# SLIMBUS2_L3Interconnect register map
Vendor: Texas Instruments
Peripheral module from a debugger description file (folder omap4460).
Registers are 32-bit, access per field, reset 0x0 unless marked. A register's access mark holds for its fields unless they carry their own. Offsets are as the file gives them; lines under a group give offsets from that group; [hi:lo] are bit positions; {n}, {i} and the like mark numbered series; 'fields as' and 'values as' point back to an identical list; <NAME> marks a mode.

## SLIMBUS2_L3Interconnect (part 1 of 2)
0x00 SLIMBUS_CMP_REVISION ro reset not defined — IP Revision Identifier Used by software to track features, bugs, and compatibility
  [31:0] REVISION — Revision Number
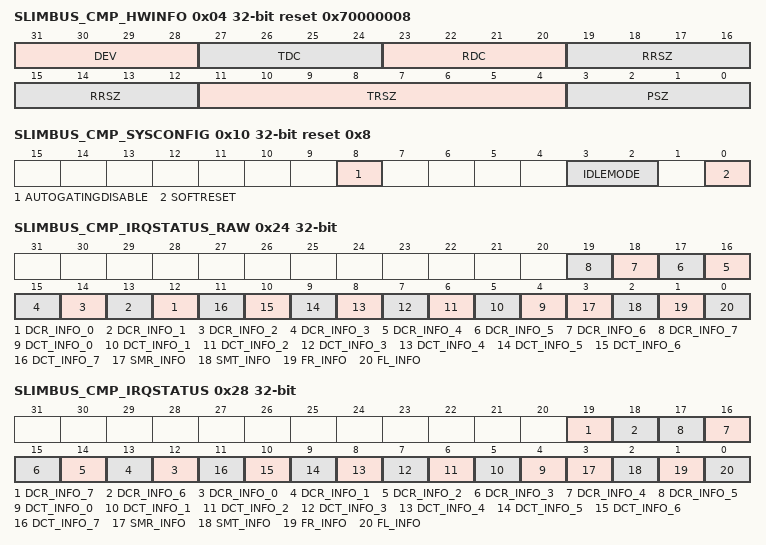
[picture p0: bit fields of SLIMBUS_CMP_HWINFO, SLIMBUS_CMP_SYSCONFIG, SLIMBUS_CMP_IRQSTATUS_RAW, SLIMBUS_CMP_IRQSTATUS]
0x04 SLIMBUS_CMP_HWINFO ro reset 0x70000008 (reset mask 0xF000000F) — Those read-only, hardcoded fields display the values of the eponymous hardware configuration depending on module instantiation - SLIMBUS1 or SLIMBUS2.
  [31:28] DEV — Device count: number of devices supported by the component, most notably through the automatically reception of the messages addressed to them. Sets the number of instances of the 'DEV_XYZ' registers.
  [27:24] TDC — Transmit Data agent Count: Number of transmit hardware data agents (FIFO and associated logic) Sets the number of instances of the 'DCT_XYZ' registers.
  [23:20] RDC — Receive Data agent Count: Number of receive hardware data agents (FIFO and associated logic) Sets the number of instances of the 'DCR_XYZ' registers.
  [19:12] RRSZ — Size of receive FIFO RAM, in 32-bit words. RX message FIFO and all RX data FIFOs map to that shared RAM.
  [11:4] TRSZ — Size of transmit FIFO RAM, in 32-bit words. TX message FIFO and all TX data FIFOs map to that shared RAM.
  [3:0] PSZ — Size of (both TX and RX) FIFO segment word pointers, in bits. Determines the maximum number of (variable-sized) segment words a data agent FIFO can contain. Sets the width of FIFO control and status fields: size, threshold, level.
0x10 SLIMBUS_CMP_SYSCONFIG reset 0x8 — This register allows controlling various parameters of the interconnect interface
  [8] AUTOGATINGDISABLE rw — Control of the internal clock autogating for safety / debug only. No impact on module functionality, only on dynamic power.
    0=Internal clocks are gated off when unused, power is optimized; 1=Internal clocks are free-running, maximum dynamic power
  [3:2] IDLEMODE rw — Configuration of the local target state management mode. By definition, target can handle read/write transaction as long as it is out of IDLE state.
    0=Force-idle mode: local target's idle state follows (acknowledges) the system's idle requests unconditionally, that is, regardless of the IP module's internal requirements. Backup mode, for debug only.; 1=No-idle mode: local target never enters idle state. Backup mode, for debug only.; 3=Smart-idle wakeup-capable mode: local target's idle state eventually follows (acknowledges) the system's idle requests, depending on the IP module's internal requirements. IP module may generate (IRQ- or DMA-request-related) wakeup events when in idle state. Mode is only relevant if the appropriate IP module 'swakeup' output(s) is (are) implemented.; 2=Smart-idle mode: local target's idle state eventually follows (acknowledges) the system's idle requests, depending on the IP module's internal requirements. IP module shall not generate (IRQ- or DMA-request-related) wakeup events.
  [0] SOFTRESET rw — Software reset. (Optional)
    0=SOFTRESET_0_w (No action); 1=SOFTRESET_1_w (Initiate software reset); 1=SOFTRESET_1_r (Reset (software or other) ongoing); 0=SOFTRESET_0_r (Reset done, no pending action)
0x24 SLIMBUS_CMP_IRQSTATUS_RAW access not given — Component (that is, main) interrupt request status. Check the corresponding secondary status register. Raw status is set even if event is not enabled. Write 1 to set the (raw) status, mostly for debug.
  [n+12] DCR_INFO_{n} (n=0..7) — IRQ status for RX Data agent {n} If implemented: (access RW W1toSet)
    0=DCR_INFO_{n}_0_w (No action); 1=DCR_INFO_{n}_1_w (Trigger IRQ event by software); 1=DCR_INFO_{n}_1_r (IRQ event pending); 0=DCR_INFO_{n}_0_r (No event pending)
  [n+4] DCT_INFO_{n} (n=0..7) — IRQ status for TX Data agent {n} (access RW W1toSet)
    0=DCT_INFO_{n}_0_w (No action); 1=DCT_INFO_{n}_1_w (Trigger IRQ event by software); 1=DCT_INFO_{n}_1_r (IRQ event pending); 0=DCT_INFO_{n}_0_r (No event pending)
  [3] SMR_INFO — IRQ status for message receive (access RW W1toSet)
    0=SMR_INFO_0_w (No action); 1=SMR_INFO_1_w (Trigger IRQ event by software); 1=SMR_INFO_1_r (IRQ event pending); 0=SMR_INFO_0_r (No event pending)
  [2] SMT_INFO — IRQ status for message transmit (access RW W1toSet)
    0=SMT_INFO_0_w (No action); 1=SMT_INFO_1_w (Trigger IRQ event by software); 1=SMT_INFO_1_r (IRQ event pending); 0=SMT_INFO_0_r (No event pending)
  [1] FR_INFO — IRQ status for Framer device, when active (access RW W1toSet)
    0=FR_INFO_0_w (No action); 1=FR_INFO_1_w (Trigger IRQ event by software); 1=FR_INFO_1_r (IRQ event pending); 0=FR_INFO_0_r (No event pending)
  [0] FL_INFO — IRQ status for Frame Layer (access RW W1toSet)
    0=FL_INFO_0_w (No action); 1=FL_INFO_1_w (Trigger IRQ event by software); 1=FL_INFO_1_r (IRQ event pending); 0=FL_INFO_0_r (No event pending)
0x28 SLIMBUS_CMP_IRQSTATUS access not given — Component (that is, main) interrupt request status. Check the corresponding secondary status register. Enabled status isn't set unless event is enabled. Write 1 to clear the status after interrupt has been serviced (raw status gets cleared, that is, even if not enabled).
  [19] DCR_INFO_7 — IRQ status for RX Data agent 7. If implemented: (access RW W1toClr)
    0=DCR_INFO_7_0_w (No action); 1=DCR_INFO_7_1_w (Clear pending event, if any); 1=DCR_INFO_7_1_r (IRQ event pending); 0=DCR_INFO_7_0_r (No event pending)
  [18] DCR_INFO_6 — IRQ status for RX Data agent 6. If implemented: (access RW W1toClr)
    0=DCR_INFO_6_0_w (No action); 1=DCR_INFO_6_1_w (Clear pending event, if any); 1=DCR_INFO_6_1_r (IRQ event pending); 0=DCR_INFO_6_0_r (No event pending)
  [n+12] DCR_INFO_{n} (n=0..5) — IRQ status for RX Data agent {n} . If implemented: (access RW W1toClr)
    0=DCR_INFO_{n}_0_w (No action); 1=DCR_INFO_{n}_1_w (Clear pending event, if any); 1=DCR_INFO_{n}_1_r (IRQ event pending); 0=DCR_INFO_{n}_0_r (No event pending)
  [n+4] DCT_INFO_{n} (n=0..7) — IRQ status for TX Data agent {n} (access RW W1toClr)
    0=DCT_INFO_{n}_0_w (No action); 1=DCT_INFO_{n}_1_w (Clear pending event, if any); 1=DCT_INFO_{n}_1_r (IRQ event pending); 0=DCT_INFO_{n}_0_r (No event pending)
  [3] SMR_INFO — IRQ status for message receive (access RW W1toClr)
    0=SMR_INFO_0_w (No action); 1=SMR_INFO_1_w (Clear pending event, if any); 1=SMR_INFO_1_r (IRQ event pending); 0=SMR_INFO_0_r (No event pending)
  [2] SMT_INFO — IRQ status for message transmit (access RW W1toClr)
    0=SMT_INFO_0_w (No action); 1=SMT_INFO_1_w (Clear pending event, if any); 1=SMT_INFO_1_r (IRQ event pending); 0=SMT_INFO_0_r (No event pending)
  [1] FR_INFO — IRQ status for Framer device, when active (access RW W1toClr)
    0=FR_INFO_0_w (No action); 1=FR_INFO_1_w (Clear pending event, if any); 1=FR_INFO_1_r (IRQ event pending); 0=FR_INFO_0_r (No event pending)
  [0] FL_INFO — IRQ status for Frame Layer (access RW W1toClr)
    0=FL_INFO_0_w (No action); 1=FL_INFO_1_w (Clear pending event, if any); 1=FL_INFO_1_r (IRQ event pending); 0=FL_INFO_0_r (No event pending)
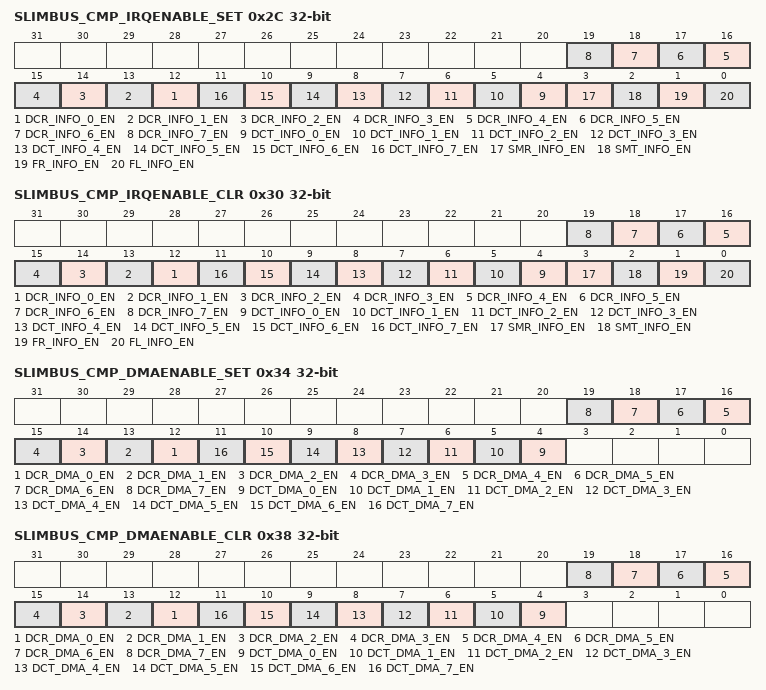
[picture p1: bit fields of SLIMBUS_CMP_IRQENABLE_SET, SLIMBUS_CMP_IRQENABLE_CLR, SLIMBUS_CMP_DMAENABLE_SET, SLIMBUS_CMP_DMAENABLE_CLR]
0x2C SLIMBUS_CMP_IRQENABLE_SET access not given — Component (that is, main) interrupt request enable Write 1 to set (enable interrupt). Readout equal to corresponding _CLR register.
  [n+12] DCR_INFO_{n}_EN (n=0..7) — IRQ enable for RX Data agent {n}. If implemented: (access RW W1toSet)
    0=DCR_INFO_{n}_EN_0_w (No action); 1=DCR_INFO_{n}_EN_1_w (Set IRQ enable (that is, enable event)); 1=DCR_INFO_{n}_EN_1_r (IRQ event is enabled); 0=DCR_INFO_{n}_EN_0_r (IRQ event is disabled)
  [n+4] DCT_INFO_{n}_EN (n=0..7) — IRQ enable for TX Data agent {n} (access RW W1toSet)
    0=DCT_INFO_{n}_EN_0_w (No action); 1=DCT_INFO_{n}_EN_1_w (Set IRQ enable (that is, enable event)); 1=DCT_INFO_{n}_EN_1_r (IRQ event is enabled); 0=DCT_INFO_{n}_EN_0_r (IRQ event is disabled)
  [3] SMR_INFO_EN — IRQ enable for message receive (access RW W1toSet)
    0=SMR_INFO_EN_0_w (No action); 1=SMR_INFO_EN_1_w (Set IRQ enable (that is, enable event)); 1=SMR_INFO_EN_1_r (IRQ event is enabled); 0=SMR_INFO_EN_0_r (IRQ event is disabled)
  [2] SMT_INFO_EN — IRQ enable for message transmit (access RW W1toSet)
    0=SMT_INFO_EN_0_w (No action); 1=SMT_INFO_EN_1_w (Set IRQ enable (that is, enable event)); 1=SMT_INFO_EN_1_r (IRQ event is enabled); 0=SMT_INFO_EN_0_r (IRQ event is disabled)
  [1] FR_INFO_EN — IRQ enable for Framer device, when active (access RW W1toSet)
    0=FR_INFO_EN_0_w (No action); 1=FR_INFO_EN_1_w (Set IRQ enable (that is, enable event)); 1=FR_INFO_EN_1_r (IRQ event is enabled); 0=FR_INFO_EN_0_r (IRQ event is disabled)
  [0] FL_INFO_EN — IRQ enable for Frame Layer (access RW W1toSet)
    0=FL_INFO_EN_0_w (No action); 1=FL_INFO_EN_1_w (Set IRQ enable (that is, enable event)); 1=FL_INFO_EN_1_r (IRQ event is enabled); 0=FL_INFO_EN_0_r (IRQ event is disabled)
0x30 SLIMBUS_CMP_IRQENABLE_CLR access not given — Component (that is, main) interrupt request enable Write 1 to clear (disable interrupt). Readout equal to corresponding _SET register.
  [n+12] DCR_INFO_{n}_EN (n=0..7) — IRQ enable for RX data agent {n}. If implemented: (access RW W1toClr)
    0=DCR_INFO_{n}_EN_0_w (No action); 1=DCR_INFO_{n}_EN_1_w (Clear IRQ enable (that is, disable event)); 1=DCR_INFO_{n}_EN_1_r (IRQ event is enabled); 0=DCR_INFO_{n}_EN_0_r (IRQ event is disabled)
  [n+4] DCT_INFO_{n}_EN (n=0..7) — IRQ enable for TX Data agent {n} (access RW W1toClr)
    0=DCT_INFO_{n}_EN_0_w (No action); 1=DCT_INFO_{n}_EN_1_w (Clear IRQ enable (that is, disable event)); 1=DCT_INFO_{n}_EN_1_r (IRQ event is enabled); 0=DCT_INFO_{n}_EN_0_r (IRQ event is disabled)
  [3] SMR_INFO_EN — IRQ enable for message receive (access RW W1toClr)
    0=SMR_INFO_EN_0_w (No action); 1=SMR_INFO_EN_1_w (Clear IRQ enable (that is, disable event)); 1=SMR_INFO_EN_1_r (IRQ event is enabled); 0=SMR_INFO_EN_0_r (IRQ event is disabled)
  [2] SMT_INFO_EN — IRQ enable for message transmit (access RW W1toClr)
    0=SMT_INFO_EN_0_w (No action); 1=SMT_INFO_EN_1_w (Clear IRQ enable (that is, disable event)); 1=SMT_INFO_EN_1_r (IRQ event is enabled); 0=SMT_INFO_EN_0_r (IRQ event is disabled)
  [1] FR_INFO_EN — IRQ enable for Framer device, when active (access RW W1toClr)
    0=FR_INFO_EN_0_w (No action); 1=FR_INFO_EN_1_w (Clear IRQ enable (that is, disable event)); 1=FR_INFO_EN_1_r (IRQ event is enabled); 0=FR_INFO_EN_0_r (IRQ event is disabled)
  [0] FL_INFO_EN — IRQ enable for Frame Layer (access RW W1toClr)
    0=FL_INFO_EN_0_w (No action); 1=FL_INFO_EN_1_w (Clear IRQ enable (that is, disable event)); 1=FL_INFO_EN_1_r (IRQ event is enabled); 0=FL_INFO_EN_0_r (IRQ event is disabled)
0x34 SLIMBUS_CMP_DMAENABLE_SET access not given — Components DMA enable (1 bit per DMA-capable channel) Write 1 to set (enable DMA). Readout equal to corresponding _CLR register.
  [n+12] DCR_DMA_{n}_EN (n=0..7) — DMA enable for RX Data agent {n} . If implemented: (access RW W1toSet.)
    0=DCR_DMA_{n}_EN_0_w (No action); 1=DCR_DMA_{n}_EN_1_w (Set DMA enable (that is, enable channel)); 1=DCR_DMA_{n}_EN_1_r (DMA channel is enabled); 0=DCR_DMA_{n}_EN_0_r (DMA chanel is disabled)
  [n+4] DCT_DMA_{n}_EN (n=0..7) — DMA enable for TX Data agent {n} (access RW W1toSet)
    0=DCT_DMA_{n}_EN_0_w (No action); 1=DCT_DMA_{n}_EN_1_w (Set DMA enable (that is, enable channel)); 1=DCT_DMA_{n}_EN_1_r (DMA channel is enabled); 0=DCT_DMA_{n}_EN_0_r (DMA chanel is disabled)
0x38 SLIMBUS_CMP_DMAENABLE_CLR access not given — Components DMA enable (1 bit per DMA-capable channel) Write 1 to clear (disable DMA). Readout equal to corresponding _SET register.
  [n+12] DCR_DMA_{n}_EN (n=0..7) — DMA enable for RX Data agent {n} . If implemented: (access RW W1toClr)
    0=DCR_DMA_{n}_EN_0_w (No action); 1=DCR_DMA_{n}_EN_1_w (Clear DMA enable (that is, disable channel)); 1=DCR_DMA_{n}_EN_1_r (DMA channel is enabled); 0=DCR_DMA_{n}_EN_0_r (DMA chanel is disabled)
  [n+4] DCT_DMA_{n}_EN (n=0..7) — DMA enable for TX Data agent {n} (access RW W1toClr)
    0=DCT_DMA_{n}_EN_0_w (No action); 1=DCT_DMA_{n}_EN_1_w (Clear DMA enable (that is, disable channel)); 1=DCT_DMA_{n}_EN_1_r (DMA channel is enabled); 0=DCT_DMA_{n}_EN_0_r (DMA chanel is disabled)
0x40 SLIMBUS_CMP_IV — Component IV field, used as lower 8 bits of the devices' Enumeration Address (EA[47:0]). Identical for all devices of the component.
  [7:0] IV rw — Device component's Instance Value (IV[7:0])
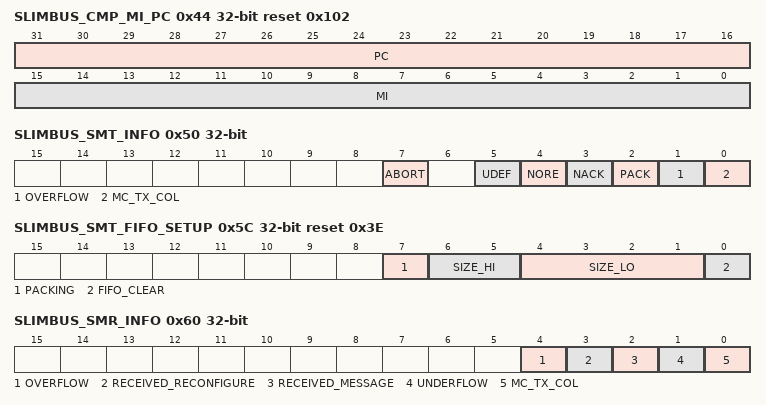
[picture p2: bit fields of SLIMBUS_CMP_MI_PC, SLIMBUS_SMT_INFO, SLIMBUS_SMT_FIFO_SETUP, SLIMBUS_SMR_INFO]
0x44 SLIMBUS_CMP_MI_PC rw reset 0x102 — Component MI and PC fields, used as upper 32 bits of the devices' Enumeration Address (EA[47:0]). Identical for all devices of the component.
  [31:16] PC — Device component's Product Code (PC[15:0])
  [15:0] MI — Device component's Manufacturer Index (MI[15:0])
0x50 SLIMBUS_SMT_INFO access not given — IRQ status for Shared Message Transmit channel. Write 1 to a bit to clear it.
  [7] ABORT — TX message was aborted before completion because of message sync loss. (access RW W1toClr)
    0=ABORT_0_w (No action); 1=ABORT_1_w (Clear pending event, if any); 1=ABORT_1_r (IRQ event pending); 0=ABORT_0_r (No event pending)
  [5] UDEF — TX message was UDEF'ed: undefined response, protocol error. (access RW W1toClr)
    0=UDEF_0_w (No action); 1=UDEF_1_w (Clear pending event, if any); 1=UDEF_1_r (IRQ event pending); 0=UDEF_0_r (No event pending)
  [4] NORE — TX message was NORE'ed: no or all-zero message response (access RW W1toClr)
    0=NORE_0_w (No action); 1=NORE_1_w (Clear pending event, if any); 1=NORE_1_r (IRQ event pending); 0=NORE_0_r (No event pending)
  [3] NACK — TX message was NACK'ed: at least one of the recipient devices requested message retransmission. (access RW W1toClr)
    0=NACK_0_w (No action); 1=NACK_1_w (Clear pending event, if any); 1=NACK_1_r (IRQ event pending); 0=NACK_0_r (No event pending)
  [2] PACK — TX message was PACK'ed: all recipient devices accepted the message. (access RW W1toClr)
    0=PACK_0_w (No action); 1=PACK_1_w (Clear pending event, if any); 1=PACK_1_r (IRQ event pending); 0=PACK_0_r (No event pending)
  [1] OVERFLOW — Overflow in TX message FIFO: Software tried to write more bytes than available in the FIFO. (access RW W1toClr)
    0=OVERFLOW_0_w (No action); 1=OVERFLOW_1_w (Clear pending event, if any); 1=OVERFLOW_1_r (IRQ event pending); 0=OVERFLOW_0_r (No event pending)
  [0] MC_TX_COL — Transmit collision in Message Channel (MC) during message transmission. Interface device class-specific information element (IE) (access RW W1toClr)
    0=MC_TX_COL_0_w (No action); 1=MC_TX_COL_1_w (Clear pending event, if any); 1=MC_TX_COL_1_r (IRQ event pending); 0=MC_TX_COL_0_r (No event pending)
0x54 SLIMBUS_SMT_MESSAGE rw — Shared Message Transmit FIFO input
  [31:0] TX_MESSAGE — TX message byte(s), depending on packing mode. Reads return 0. Enter the whole message except last byte (Message Integrity MI and Response MR), and with a don't care placeholder for Primary Integrity (PI).
0x58 SLIMBUS_SMT_CONTROL — Control of Shared Message channel Transmission.
  [0] MESSAGE_ENABLE rw — Enable the transmission of the message(s) previously written into the TX Message FIFO, with unlimited arbitration auto-retries. Self-cleared after either a message not get PACK'ed or the FIFO is empty.
    0=MESSAGE_ENABLE_0_w (No effect); 1=MESSAGE_ENABLE_1_w (Request transmission of stored messages); 1=MESSAGE_ENABLE_1_r (Message transmission is ongoing); 0=MESSAGE_ENABLE_0_r (Message transmission is stopped / complete)
0x5C SLIMBUS_SMT_FIFO_SETUP reset 0x3E — Shared Message Transmit channel configuration. To be kept static during operation. Note that message segment word size is 2 slots = 1 byte (= message size granularity) and that message FIFO base address is always 0x0.
  [7] PACKING rw — Packing enable control for TX message FIFO
    0=Packing disabled: one byte per access only (LSByte), byte enable is don't care; 1=Packing enabled: one or several bytes per access, depending on byte enable
  [6:5] SIZE_HI rw — (Upper bits of the) capacity of shared TX message FIFO, in bytes, minus one. To be set for largest supported (transmitted) message(s).
    0=16 bytes (minimum size); 1=32 bytes (recommended); 3=64 bytes (max size); 2=48 bytes (large messages)
  [4:1] SIZE_LO ro — (Lower bits of the) capacity of shared TX message FIFO, in bytes, minus one. Read-only, for reference only.
  [0] FIFO_CLEAR rw — Returns FIFO to initial empty state.
    0=FIFO_CLEAR_0_w (No effect); 1=FIFO_CLEAR_1_w (Clear FIFO); 1=FIFO_CLEAR_1_r (Ongoing Clear. Completion requires the SLIMbus clock.); 0=FIFO_CLEAR_0_r (No event, last clear completed)
0x60 SLIMBUS_SMR_INFO access not given — IRQ status for Shared Message Receive channel. Write 1 to a bit to clear it.
  [4] OVERFLOW — Overflow in RX message FIFO: received message is larger than the FIFO. (access RW W1toClr)
    0=OVERFLOW_0_w (no action); 1=OVERFLOW_1_w (clear event); 1=OVERFLOW_1_r (event pending); 0=OVERFLOW_0_r (no event pending)
  [3] RECEIVED_RECONFIGURE — RECONFIGURE_NOW message received, available in RX message FIFO (access RW W1toClr)
    0=RECEIVED_RECONFIGURE_0_w (no action); 1=RECEIVED_RECONFIGURE_1_w (clear event); 1=RECEIVED_RECONFIGURE_1_r (event pending); 0=RECEIVED_RECONFIGURE_0_r (no event pending)
  [2] RECEIVED_MESSAGE — Message available in the RX message FIFO. Clear bit to clear the FIFO and allow the reception of further messages (incoming messages will be NACK'ed until then). (access RW W1toClr)
    0=RECEIVED_MESSAGE_0_w (no action); 1=RECEIVED_MESSAGE_1_w (clear event, clear FIFO, allow further messages.); 1=RECEIVED_MESSAGE_1_r (event pending); 0=RECEIVED_MESSAGE_0_r (no event pending)
  [1] UNDERFLOW — Underflow in RX message FIFO: Software tried to read out more bytes than available. (access RW W1toClr)
    0=UNDERFLOW_0_w (no action); 1=UNDERFLOW_1_w (clear event); 1=UNDERFLOW_1_r (event pending); 0=UNDERFLOW_0_r (no event pending)
  [0] MC_TX_COL — Transmit collision in Message Channel (MC) during RX message during message reception. Interface device class-specific information element (IE) (access RW W1toClr)
    0=MC_TX_COL_0_w (no action); 1=MC_TX_COL_1_w (clear event); 1=MC_TX_COL_1_r (event pending); 0=MC_TX_COL_0_r (no event pending)
0x64 SLIMBUS_SMR_MESSAGE ro — Shared Message Receive channel FIFO output.
  [31:0] RX_MESSAGE — RX message byte(s), depending on packing mode. Writes have no effect. Readout value from an empty FIFO is undefined, that is, there is no defined 'reset value'. Message is guaranteed to have destination address matching a local device address (LA or EA), correct Primary and Message Integrity (PI and MI) and PACK Message Response (MR). Whole message available for readout, including the last byte (Message Integrity MI and Response MR)
0x68 SLIMBUS_SMR_CONTROL — Control of Shared Message channel Reception.
  [0] MESSAGE_DISABLE rw — Disables the reception of incoming messages (that is, broadcast or locally addressed) into the RX Message FIFO. Same effect for the same value than SMR_INFO[2] RECEIVED_MESSAGE, but this bit can be set to 1.
    0=Enabled: incoming messages will be PACK'ed; 1=Disabled: incoming messages will be NACK'ed
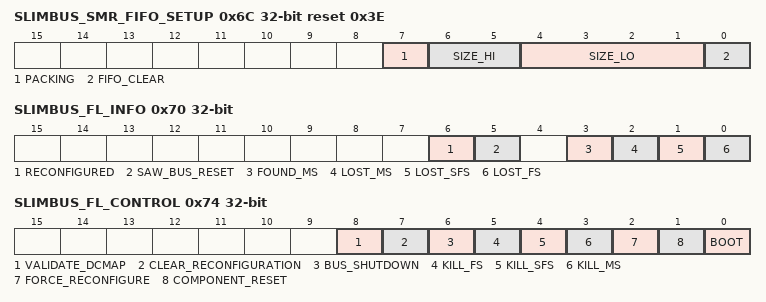
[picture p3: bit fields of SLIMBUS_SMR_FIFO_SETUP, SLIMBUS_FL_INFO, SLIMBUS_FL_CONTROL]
0x6C SLIMBUS_SMR_FIFO_SETUP reset 0x3E — Shared Message Receive channel setup. To be kept static during operation. Note that message segment word size is 2 slots = 1 byte (= message size granularity) and that message FIFO base address is always 0x0.
  [7] PACKING rw — Packing enable control for RX message FIFO
    values as SLIMBUS_SMT_FIFO_SETUP.PACKING
  [6:5] SIZE_HI rw — (Upper bits of the) capacity of shared RX message FIFO, in bytes, minus one. To be set for largest supported (received) message.
    values as SLIMBUS_SMT_FIFO_SETUP.SIZE_HI
  [4:1] SIZE_LO ro — (Lower bits of the) capacity of shared RX message FIFO, in bytes, minus one. Read-only, for reference only.
  [0] FIFO_CLEAR rw — Returns message FIFO to initial empty state.
    values as SLIMBUS_SMT_FIFO_SETUP.FIFO_CLEAR
0x70 SLIMBUS_FL_INFO access not given — Frame Layer IRQ status. Write 1 to a bit to clear it. Note: FS loss implies SFS loss, and SFS loss implies MS loss, but only the 'strongest' loss event is logged for a given event.
  [6] RECONFIGURED — Reconfiguration boundary crossed (access RW W1toClr)
    0=RECONFIGURED_0_w (No action); 1=RECONFIGURED_1_w (Clear pending event, if any); 1=RECONFIGURED_1_r (IRQ event pending); 0=RECONFIGURED_0_r (No event pending)
  [5] SAW_BUS_RESET — Bus reset sequence detected on the bus: no activity on DATA line (all-zero) for 2 to 4 frames. Clock receiver FSM has returned to Reset state. Should trigger a local component reset (software sequence). (access RW W1toClr)
    0=SAW_BUS_RESET_0_w (No action); 1=SAW_BUS_RESET_1_w (Clear pending event, if any); 1=SAW_BUS_RESET_1_r (IRQ event pending); 0=SAW_BUS_RESET_0_r (No event pending)
  [3] FOUND_MS — Message sync was acquired: operational state reached (access RW W1toClr)
    0=FOUND_MS_0_w (No action); 1=FOUND_MS_1_w (Clear pending event, if any); 1=FOUND_MS_1_r (IRQ event pending); 0=FOUND_MS_0_r (No event pending)
  [2] LOST_MS — Message Synchronization was lost Interface device class-specific information element (IE) Note: Not asserted in case of FS or SFS loss. (access RW W1toClr)
    0=LOST_MS_0_w (No action); 1=LOST_MS_1_w (Clear pending event, if any); 1=LOST_MS_1_r (IRQ event pending); 0=LOST_MS_0_r (No event pending)
  [1] LOST_SFS — Super Frame Synchronization was lost Interface device class-specific information element (IE) Note: Not asserted in case of FS loss. (access RW W1toClr)
    0=LOST_SFS_0_w (No action); 1=LOST_SFS_1_w (Clear pending event, if any); 1=LOST_SFS_1_r (IRQ event pending); 0=LOST_SFS_0_r (No event pending)
  [0] LOST_FS — Frame Synchronization was lost Interface device class-specific information element (IE) (access RW W1toClr)
    0=LOST_FS_0_w (No action); 1=LOST_FS_1_w (Clear pending event, if any); 1=LOST_FS_1_r (IRQ event pending); 0=LOST_FS_0_r (No event pending)
0x74 SLIMBUS_FL_CONTROL — Frame Layer control. (Self-cleared bits)
  [8] VALIDATE_DCMAP rw — Validates the mapping of data channels on devices: to be used after modifying the DC*_MAP* fields (DI and PN).
    0=VALIDATE_DCMAP_0_w (No action); 1=VALIDATE_DCMAP_1_w (Validates all DCT_MAP / DCR_MAP values)
  [7] CLEAR_RECONFIGURATION rw — Clear all updates cumulated since the last reconfiguration, return reconfiguration fields to currently active value. Self-cleared immediately.
    0=CLEAR_RECONFIGURATION_0_w (No action); 1=CLEAR_RECONFIGURATION_1_w
  [6] BUS_SHUTDOWN rw — Sets both the clock source or the clock receiver FSMs back to 'Undefined' state at the next reconfiguration boundary. Executed (and bit self-cleared) on next reconfiguration (forced or not); also cleared by a 'clear_reconfiguration'.
    0=BUS_SHUTDOWN_0_w (Cancel pending request (not used in normal operation) if any, otherwise no action); 1=BUS_SHUTDOWN_1_w (Assert request for next reconfiguration); 1=BUS_SHUTDOWN_1_r (Request pending for next reconfiguration); 0=BUS_SHUTDOWN_0_r (No request pending for next reconfiguration)
  [5] KILL_FS rw — Force immediate Frame Synchronization loss (implying as well message and superframe sync) When in 'Operational', 'SeekingMessageSync' or 'SeekingSuperFrameSync' states, component shall go to 'SeekingFrameSync' and start reaquiring frame sync. No effect otherwise. For debug use.
    0=KILL_FS_0_w (No action); 1=KILL_FS_1_w (Force frame sync loss); 0=KILL_FS_0_r (Always reads 0 because of immediate action.)
  [4] KILL_SFS rw — Force SuperFrame Synchronization loss at next reconfiguration boundary (implying as well message sync loss). When in 'Operational' or 'SeekingMessageSync' states, component shall go to 'SeekingSuperFrameSync' and start reaquiring superframe sync. No effect otherwise. Used by clock receiver component upon imcompletely received reconfiguration sequence.
    0=KILL_SFS_0_w (No action); 1=KILL_SFS_1_w (Schedule superframe sync loss); 1=KILL_SFS_1_r (Superframe sync loss pending); 0=KILL_SFS_0_r (No pending superframe sync loss)
  [3] KILL_MS rw — Force an immediate Message Synchronization loss. When in 'Operational' state, component shall go to 'SeekingMessageSync' and start reaquiring message sync. No effect otherwise. For debug use.
    0=KILL_MS_0_w (No action); 1=KILL_MS_1_w (Force message sync loss); 0=KILL_MS_0_r (Always reads 0 because of immediate action.)
  [2] FORCE_RECONFIGURE rw — Force a reconfiguration boundary at next superframe boundary, rather than wait for a RECONFIGURE_NOW() message.
    0=FORCE_RECONFIGURE_0_w (Cancel pending request (not used in normal operation) if any, otherwise no action); 1=FORCE_RECONFIGURE_1_w (Assert reconfiguration request for next superframe boundary); 1=FORCE_RECONFIGURE_1_r (Reconfiguration request pending for next superframe boundary); 0=FORCE_RECONFIGURE_0_r (No request pending)
  [1] COMPONENT_RESET rw — Component reset request control: Transitions clock receiver FSM to state 'Reset' (from any other state). Immediate action. Set upon reception of the RESET_DEVICE() message by the interface device, which requires a component-level reset. Note that a component-level reset is also required in case of bus reset, but the transition to 'Reset' state happens automatically in that case and this bit is not used.
    1=COMPONENT_RESET_1_w (Assert request for next reconfiguration)
  [0] BOOT rw — Boot the component when not in active framer mode (don't care when in active framer mode). Transitions clock receiver FSM from state 'Undefined' to 'Reset'.
    0=No action; 1=Enable clock receiver boot sequence
